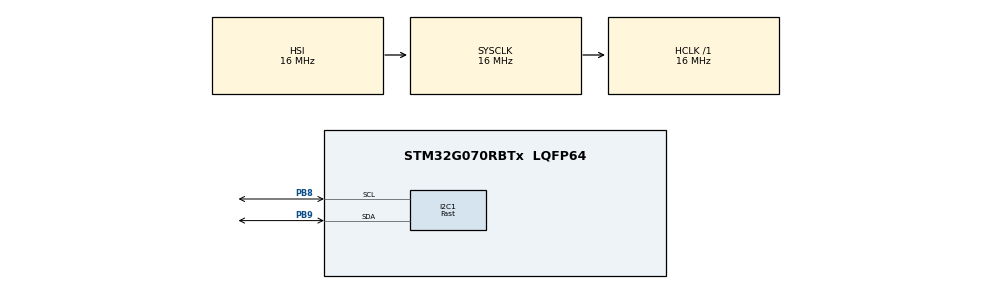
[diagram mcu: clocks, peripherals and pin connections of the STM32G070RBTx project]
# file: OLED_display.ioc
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I2C1.Analog_Filter=I2C_ANALOGFILTER_DISABLE
I2C1.CustomTiming=Disabled
I2C1.I2C_Fall_Time=2
I2C1.I2C_Rise_Time=2
I2C1.I2C_Speed_Mode=I2C_Fast
I2C1.Timing=0x0010071B
Mcu.Family=STM32G0
Mcu.Name=STM32G070RBTx
Mcu.Package=LQFP64
PB8.Mode=I2C
PB8.Signal=I2C1_SCL
PB9.Mode=I2C
PB9.Signal=I2C1_SDA
ProjectManager.HeapSize=0x200
ProjectManager.StackSize=0x400
ProjectManager.TargetToolchain=STM32CubeIDE
RCC.AHBFreq_Value=16000000
RCC.CortexFreq_Value=16000000
RCC.EXTERNAL_CLOCK_VALUE=48000
RCC.HCLKFreq_Value=16000000
RCC.HSE_VALUE=8000000
RCC.HSI_VALUE=16000000
RCC.LSE_VALUE=32768
RCC.SYSCLKFreq_VALUE=16000000
RCC.VCOOutputFreq_Value=128000000
VP_SYS_VS_DBSignals.Mode=DisableDeadBatterySignals
board=custom

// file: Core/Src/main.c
/* USER CODE BEGIN Header */
/**
  ******************************************************************************
  * @file           : main.c
  * @brief          : Main program body
  ******************************************************************************
  * @attention
  *
  * <h2><center>&copy; Copyright (c) 2022 STMicroelectronics.
  * All rights reserved.</center></h2>
  *
  * This software component is licensed by ST under BSD 3-Clause license,
  * the "License"; You may not use this file except in compliance with the
  * License. You may obtain a copy of the License at:
  *                        opensource.org/licenses/BSD-3-Clause
  *
  ******************************************************************************
  */
/* USER CODE END Header */
#include "main.h"

/* USER CODE BEGIN Includes */
#include "fonts.h"
#include "ssd1306.h"
#include "test.h"
#include "bitmap.h"
#include "horse_anim.h"
/* USER CODE END Includes */

I2C_HandleTypeDef hi2c1;

void SystemClock_Config(void);
static void MX_GPIO_Init(void);
static void MX_I2C1_Init(void);

int main(void)
{

  /* MCU Configuration--------------------------------------------------------*/

  /* Reset of all peripherals, Initializes the Flash interface and the Systick. */
  HAL_Init();

  /* Configure the system clock */
  SystemClock_Config();

  /* Initialize all configured peripherals */
  MX_GPIO_Init();
  MX_I2C1_Init();
  /* USER CODE BEGIN 2 */
  SSD1306_Init();  // initialise

  SSD1306_GotoXY (0,0);
      SSD1306_Puts ("HELLO", &Font_11x18, 1);
      SSD1306_GotoXY (10, 30);
      SSD1306_Puts ("  WORLD :)", &Font_11x18, 1);
      SSD1306_UpdateScreen(); //display

      HAL_Delay (2000);

      SSD1306_ScrollRight(0,7);  // scroll entire screen
      HAL_Delay(2000);  // 2 sec

      SSD1306_ScrollLeft(0,7);  // scroll entire screen
      HAL_Delay(2000);  // 2 sec

      SSD1306_Stopscroll();
      SSD1306_Clear();

      SSD1306_DrawBitmap(0,0,logo, 128, 64, 1);
      SSD1306_UpdateScreen();

      HAL_Delay(2000);

      SSD1306_ScrollRight(0x00, 0x0f);    // scroll entire screen right

      HAL_Delay (2000);

      SSD1306_ScrollLeft(0x00, 0x0f);  // scroll entire screen left

      HAL_Delay (2000);

      SSD1306_Scrolldiagright(0x00, 0x0f);  // scroll entire screen diagonal right

      HAL_Delay (2000);

      SSD1306_Scrolldiagleft(0x00, 0x0f);  // scroll entire screen diagonal left

      HAL_Delay (2000);

      SSD1306_Stopscroll();   // stop scrolling. If not done, screen will keep on scrolling

      SSD1306_InvertDisplay(1);   // invert the display

      HAL_Delay(2000);

      SSD1306_InvertDisplay(0);  // normalize the display
  //

      HAL_Delay(2000);
  /* USER CODE END 2 */

  /* Infinite loop */
  while (1)
  {
	  SSD1306_Clear();
	  SSD1306_DrawBitmap(0,0,horse1,128,64,1);
	  SSD1306_UpdateScreen();

	  SSD1306_Clear();
	  SSD1306_DrawBitmap(0,0,horse2,128,64,1);
	  SSD1306_UpdateScreen();

	  SSD1306_Clear();
	  SSD1306_DrawBitmap(0,0,horse3,128,64,1);
	  SSD1306_UpdateScreen();

	  SSD1306_Clear();
	  SSD1306_DrawBitmap(0,0,horse4,128,64,1);
	  SSD1306_UpdateScreen();

	  SSD1306_Clear();
	  SSD1306_DrawBitmap(0,0,horse5,128,64,1);
	  SSD1306_UpdateScreen();

	  SSD1306_Clear();
	  SSD1306_DrawBitmap(0,0,horse6,128,64,1);
	  SSD1306_UpdateScreen();

	  SSD1306_Clear();
	  SSD1306_DrawBitmap(0,0,horse7,128,64,1);
	  SSD1306_UpdateScreen();

	  SSD1306_Clear();
	  SSD1306_DrawBitmap(0,0,horse8,128,64,1);
	  SSD1306_UpdateScreen();

	  SSD1306_Clear();
	  SSD1306_DrawBitmap(0,0,horse9,128,64,1);
	  SSD1306_UpdateScreen();

	  SSD1306_Clear();
	  SSD1306_DrawBitmap(0,0,horse10,128,64,1);
	  SSD1306_UpdateScreen();
  }
}

void SystemClock_Config(void)
{
  RCC_OscInitTypeDef RCC_OscInitStruct = {0};
  RCC_ClkInitTypeDef RCC_ClkInitStruct = {0};
  RCC_PeriphCLKInitTypeDef PeriphClkInit = {0};

  /** Configure the main internal regulator output voltage
  */
  HAL_PWREx_ControlVoltageScaling(PWR_REGULATOR_VOLTAGE_SCALE1);
  /** Initializes the RCC Oscillators according to the specified parameters
  * in the RCC_OscInitTypeDef structure.
  */
  RCC_OscInitStruct.OscillatorType = RCC_OSCILLATORTYPE_HSI;
  RCC_OscInitStruct.HSIState = RCC_HSI_ON;
  RCC_OscInitStruct.HSIDiv = RCC_HSI_DIV1;
  RCC_OscInitStruct.HSICalibrationValue = RCC_HSICALIBRATION_DEFAULT;
  RCC_OscInitStruct.PLL.PLLState = RCC_PLL_NONE;
  if (HAL_RCC_OscConfig(&RCC_OscInitStruct) != HAL_OK)
  {
    Error_Handler();
  }
  /** Initializes the CPU, AHB and APB buses clocks
  */
  RCC_ClkInitStruct.ClockType = RCC_CLOCKTYPE_HCLK|RCC_CLOCKTYPE_SYSCLK
                              |RCC_CLOCKTYPE_PCLK1;
  RCC_ClkInitStruct.SYSCLKSource = RCC_SYSCLKSOURCE_HSI;
  RCC_ClkInitStruct.AHBCLKDivider = RCC_SYSCLK_DIV1;
  RCC_ClkInitStruct.APB1CLKDivider = RCC_HCLK_DIV1;

  if (HAL_RCC_ClockConfig(&RCC_ClkInitStruct, FLASH_LATENCY_0) != HAL_OK)
  {
    Error_Handler();
  }
  /** Initializes the peripherals clocks
  */
  PeriphClkInit.PeriphClockSelection = RCC_PERIPHCLK_I2C1;
  PeriphClkInit.I2c1ClockSelection = RCC_I2C1CLKSOURCE_PCLK1;
  if (HAL_RCCEx_PeriphCLKConfig(&PeriphClkInit) != HAL_OK)
  {
    Error_Handler();
  }
}

static void MX_I2C1_Init(void)
{

  hi2c1.Instance = I2C1;
  hi2c1.Init.Timing = 0x0010071B;
  hi2c1.Init.OwnAddress1 = 0;
  hi2c1.Init.AddressingMode = I2C_ADDRESSINGMODE_7BIT;
  hi2c1.Init.DualAddressMode = I2C_DUALADDRESS_DISABLE;
  hi2c1.Init.OwnAddress2 = 0;
  hi2c1.Init.OwnAddress2Masks = I2C_OA2_NOMASK;
  hi2c1.Init.GeneralCallMode = I2C_GENERALCALL_DISABLE;
  hi2c1.Init.NoStretchMode = I2C_NOSTRETCH_DISABLE;
  if (HAL_I2C_Init(&hi2c1) != HAL_OK)
  {
    Error_Handler();
  }
  /** Configure Analogue filter
  */
  if (HAL_I2CEx_ConfigAnalogFilter(&hi2c1, I2C_ANALOGFILTER_DISABLE) != HAL_OK)
  {
    Error_Handler();
  }
  /** Configure Digital filter
  */
  if (HAL_I2CEx_ConfigDigitalFilter(&hi2c1, 0) != HAL_OK)
  {
    Error_Handler();
  }

}

static void MX_GPIO_Init(void)
{

  /* GPIO Ports Clock Enable */
  __HAL_RCC_GPIOB_CLK_ENABLE();

}

void Error_Handler(void)
{
  __disable_irq();
  while (1)
  {
  }
}

/************************ (C) COPYRIGHT STMicroelectronics *****END OF FILE****/
